# f2838x_cm_cpu1tocm_ipc_regs register map
Vendor: Texas Instruments
Peripheral module from a debugger description file (folder C2000).
Address unit: 16 bits
Registers are 32-bit, read-write, no defined reset value unless marked. A register's access mark holds for its fields unless they carry their own. Offsets are as the file gives them; lines under a group give offsets from that group; [hi:lo] are bit positions; {n}, {i} and the like mark numbered series; 'fields as' and 'values as' point back to an identical list; <NAME> marks a mode.

## CPU1TOCM_IPC_REGS_CMVIEW — CPU1TOCM IPC Registers
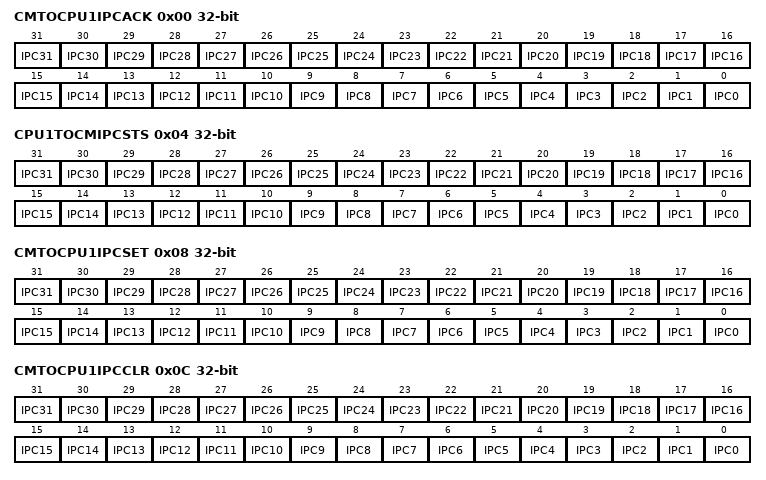
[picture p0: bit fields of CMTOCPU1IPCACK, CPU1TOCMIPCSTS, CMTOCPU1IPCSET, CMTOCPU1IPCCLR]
0x00 CMTOCPU1IPCACK
  [n] IPC{n} (n=0..31) — Acknowledgement from CM to CPU1TOCMIPCFLG.IPC{n} bit
0x04 CPU1TOCMIPCSTS ro
  [n] IPC{n} (n=0..31) — IPC{n} Request from CPU1 to CM
0x08 CMTOCPU1IPCSET
  [n] IPC{n} (n=0..31) — Set CMTOCPU1IPCFLG.IPC{n} Flag
0x0C CMTOCPU1IPCCLR
  [n] IPC{n} (n=0..31) — Clear CMTOCPU1IPCFLG.IPC{n} Flag
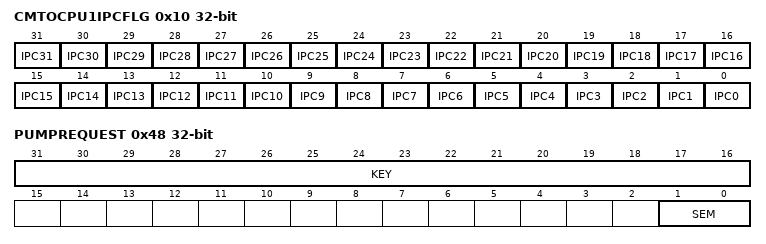
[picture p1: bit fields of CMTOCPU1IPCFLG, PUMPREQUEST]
0x10 CMTOCPU1IPCFLG ro
  [n] IPC{n} (n=0..31) — CM to CPU1 IPC{n} Flag Status
0x18 IPCCOUNTERL ro
  [31:0] COUNT — IPC Counter's lower 32-bit
0x1C IPCCOUNTERH ro
  [31:0] COUNT — IPC Counter's upper 32-bit
0x20 CPU1TOCMIPCRECVCOM ro
  [31:0] COMMAND — Refelects the state of CPU1TOCMIPCSENDCOM register
0x24 CPU1TOCMIPCRECVADDR ro
  [31:0] ADDRESS — Refelects the state of CPU1TOCMIPCSENDADDR register
0x28 CPU1TOCMIPCRECVDATA ro
  [31:0] WDATA — Refelects the state of CPU1TOCMIPCSENDDATA register
0x2C CMTOCPU1IPCREPLY
  [31:0] RDATA — CM to CPU1 IPC Reply
0x30 CMTOCPU1IPCSENDCOM
  [31:0] COMMAND — CM to CPU1 IPC Command
0x34 CMTOCPU1IPCSENDADDR
  [31:0] ADDRESS — CM to CPU1 IPC Address
0x38 CMTOCPU1IPCSENDDATA
  [31:0] WDATA — CM to CPU1 IPC Data
0x3C CPU1TOCMIPCREPLY
  [31:0] RDATA — CPU1 to CM IPC Reply
0x40 CMTOCPU1IPCBOOTSTS
  [31:0] BOOTSTS — CM to CPU1 IPC Boot Status
0x44 CPU1TOCMIPCBOOTMODE
  [31:0] BOOTMODE — CPU1 to CM IPC Boot Mode.
0x48 PUMPREQUEST
  [31:16] KEY — Key Qualifier for writes to this register
  [1:0] SEM — Flash Pump Request Semaphore between CPU1, CPU2 and CM
